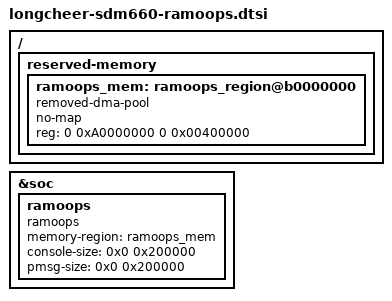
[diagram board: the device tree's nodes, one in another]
/* Copyright (c) 2019, The Linux Foundation. All rights reserved.
 *
 * This program is free software; you can redistribute it and/or modify
 * it under the terms of the GNU General Public License version 2 and
 * only version 2 as published by the Free Software Foundation.
 *
 * This program is distributed in the hope that it will be useful,
 * but WITHOUT ANY WARRANTY; without even the implied warranty of
 * MERCHANTABILITY or FITNESS FOR A PARTICULAR PURPOSE.  See the
 * GNU General Public License for more details.
 */

/* ramoops dts configuration */
/ {
	reserved-memory {
		ramoops_mem: ramoops_region@b0000000 {
			compatible = "removed-dma-pool";
			no-map;
			reg = <0 0xA0000000 0 0x00400000>;
		};
	};
};

&soc {
	ramoops {
		compatible = "ramoops";
		memory-region = <&ramoops_mem>;
		console-size = <0x0 0x200000>;
		pmsg-size = <0x0 0x200000>;
	};
};
